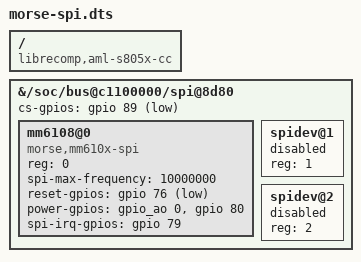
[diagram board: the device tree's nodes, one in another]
/dts-v1/;
/plugin/;

/ {
    compatible = "librecomp,aml-s805x-cc", "amlogic,meson-gxl";

    fragment@0 {
        /* This matches the exact path from your dmesg log output */
        target-path = "/soc/bus@c1100000/spi@8d80"; 
        
        __overlay__ {
            status = "okay";
            #address-cells = <1>;
            #size-cells   = <0>;

            /* CS pin: Chip 1, Line 89 (Physical Pin 24) */
            cs-gpios = <&gpio 89 1>; 

            mm6108@0 {
                compatible = "morse,mm610x-spi";
                reg = <0>;
                spi-max-frequency = <10000000>;

                /* RESET: Chip 1, Line 76 (Physical Pin 29) */
                reset-gpios    = <&gpio 76 1>;

                /* POWER: WAKE is Chip 0 Line 0 (Pin 5) | BUSY is Chip 1 Line 80 (Pin 26) */
                power-gpios    = <&gpio_ao 0 0>, <&gpio 80 0>;

                /* IRQ: Chip 1, Line 79 (Physical Pin 22) */
                spi-irq-gpios  = <&gpio 79 0>;

                status = "okay";
            };

            spidev@1 { reg = <1>; status = "disabled"; };
            spidev@2 { reg = <2>; status = "disabled"; };
        };
    };
};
